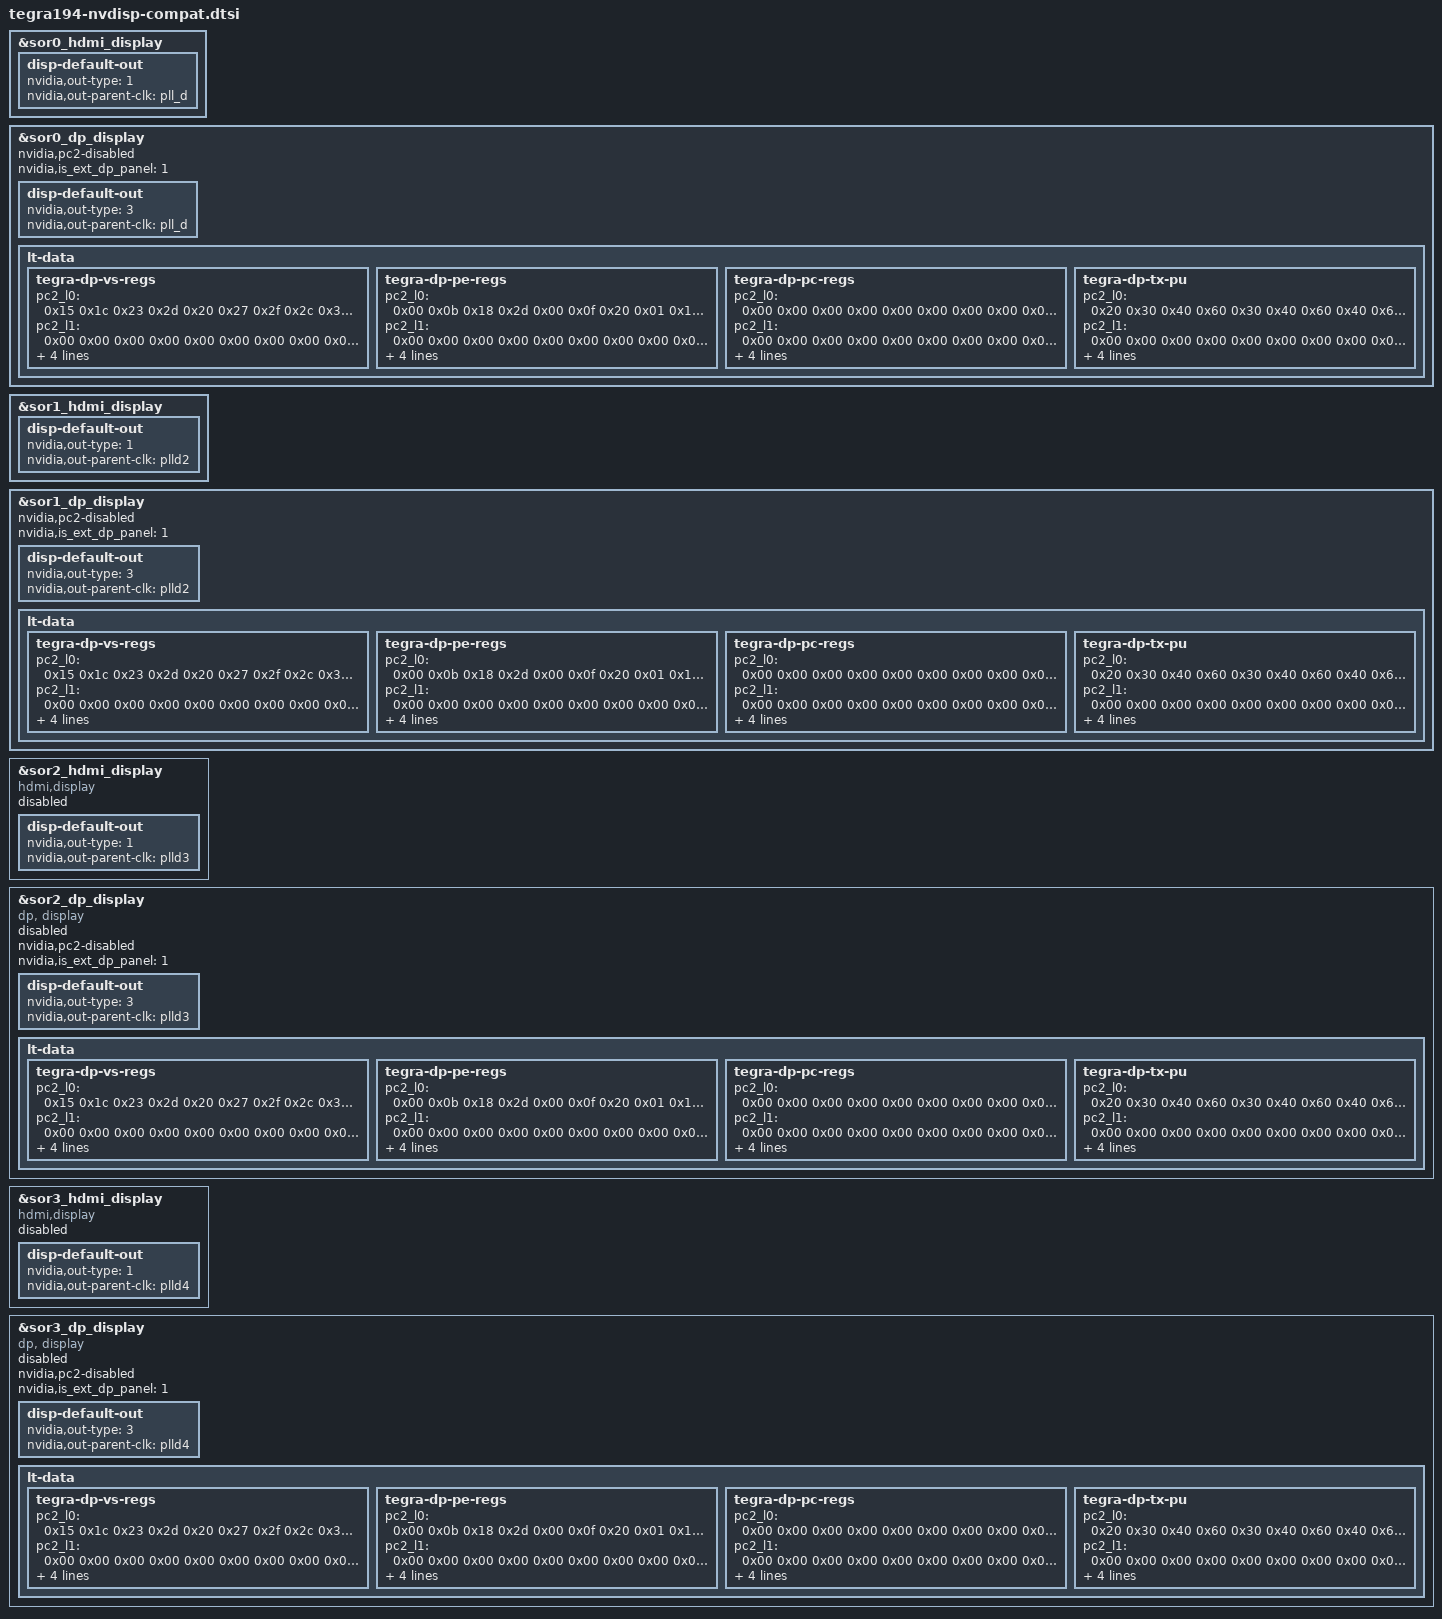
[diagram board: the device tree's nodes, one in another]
/*
 * Copyright (c) 2014-2023, NVIDIA CORPORATION.  All rights reserved.
 *
 * This program is free software; you can redistribute it and/or modify it
 * under the terms and conditions of the GNU General Public License,
 * version 2, as published by the Free Software Foundation.
 *
 * This program is distributed in the hope it will be useful, but WITHOUT
 * ANY WARRANTY; without even the implied warranty of MERCHANTABILITY or
 * FITNESS FOR A PARTICULAR PURPOSE.  See the GNU General Public License for
 * more details.
 *
 * You should have received a copy of the GNU General Public License
 * along with this program.  If not, see <http://www.gnu.org/licenses/>.
 */

/*
 * tegra194-soc-compat.dtsi: Tegra194 soc dtsi file for compatibility nodes
 * only pertaining to nvdisp/cboot display initialization prior to uefi
 */

&sor0_hdmi_display {
	disp-default-out {
		nvidia,out-type = <1>; // TEGRA_DC_OUT_HDMI
		nvidia,out-parent-clk = "pll_d";
	};
};

&sor0_dp_display {
	nvidia,pc2-disabled;
	nvidia,is_ext_dp_panel = <1>;
	disp-default-out {
		nvidia,out-type = <3>; // TEGRA_DC_OUT_DP
		nvidia,out-parent-clk = "pll_d";
	};
	lt-data {
		tegra-dp-vs-regs {
			/* postcursor2 L0 */
			pc2_l0 = <
				/* pre-emphasis: L0, L1, L2, L3 */
				0x15 0x1c 0x23 0x2d /* voltage swing: L0 */
				0x20 0x27 0x2f /* L1 */
				0x2c 0x36 /* L2 */
				0x3c /* L3 */
			>;
			/* postcursor2 L1 - UNUSED */
			pc2_l1 = <
				0x00 0x00 0x00 0x00
				0x00 0x00 0x00
				0x00 0x00
				0x00
			>;
			/* postcursor2 L2 - UNUSED */
			pc2_l2 = <
				0x00 0x00 0x00 0x00
				0x00 0x00 0x00
				0x00 0x00
				0x00
			>;
			/* postcursor2 L3 - UNUSED */
			pc2_l3 = <
				0x00 0x00 0x00 0x00
				0x00 0x00 0x00
				0x00 0x00
				0x00
			>;
		};
		tegra-dp-pe-regs {
			/* postcursor2 L0 */
			pc2_l0 = <
				/* pre-emphasis: L0, L1, L2, L3 */
				0x00 0x0b 0x18 0x2d /* voltage swing: L0 */
				0x00 0x0f 0x20 /* L1 */
				0x01 0x18 /* L2 */
				0x00 /* L3 */
			>;
			/* postcursor2 L1 - UNUSED */
			pc2_l1 = <
				0x00 0x00 0x00 0x00
				0x00 0x00 0x00
				0x00 0x00
				0x00
			>;
			/* postcursor2 L2 - UNUSED */
			pc2_l2 = <
				0x00 0x00 0x00 0x00
				0x00 0x00 0x00
				0x00 0x00
				0x00
			>;
			/* postcursor2 L3 - UNUSED */
			pc2_l3 = <
				0x00 0x00 0x00 0x00
				0x00 0x00 0x00
				0x00 0x00
				0x00
			>;
		};
		tegra-dp-pc-regs {
			/* postcursor2 L0 */
			pc2_l0 = <
				/* pre-emphasis: L0, L1, L2, L3 */
				0x00 0x00 0x00 0x00 /* voltage swing: L0 */
				0x00 0x00 0x00 /* L1 */
				0x00 0x00 /* L2 */
				0x00 /* L3 */
			>;
			/* postcursor2 L1 - UNUSED */
			pc2_l1 = <
				0x00 0x00 0x00 0x00
				0x00 0x00 0x00
				0x00 0x00
				0x00
			>;
			/* postcursor2 L2 - UNUSED */
			pc2_l2 = <
				0x00 0x00 0x00 0x00
				0x00 0x00 0x00
				0x00 0x00
				0x00
			>;
			/* postcursor2 L3 - UNUSED */
			pc2_l3 = <
				0x00 0x00 0x00 0x00
				0x00 0x00 0x00
				0x00 0x00
				0x00
			>;
		};
		tegra-dp-tx-pu {
			/* postcursor2 L0 */
			pc2_l0 = <
				/* pre-emphasis: L0, L1, L2, L3 */
				0x20 0x30 0x40 0x60 /* voltage swing: L0 */
				0x30 0x40 0x60 /* L1 */
				0x40 0x60 /* L2 */
				0x60 /* L3 */
			>;
			/* postcursor2 L1 - UNUSED */
			pc2_l1 = <
				0x00 0x00 0x00 0x00
				0x00 0x00 0x00
				0x00 0x00
				0x00
			>;
			/* postcursor2 L2 - UNUSED */
			pc2_l2 = <
				0x00 0x00 0x00 0x00
				0x00 0x00 0x00
				0x00 0x00
				0x00
			>;
			/* postcursor2 L3 - UNUSED */
			pc2_l3 = <
				0x00 0x00 0x00 0x00
				0x00 0x00 0x00
				0x00 0x00
				0x00
			>;
		};
	};
};

&sor1_hdmi_display {
	disp-default-out {
		nvidia,out-type = <1>; // TEGRA_DC_OUT_HDMI
		nvidia,out-parent-clk = "plld2";
	};
};

&sor1_dp_display {
	nvidia,pc2-disabled;
	nvidia,is_ext_dp_panel = <1>;
	disp-default-out {
		nvidia,out-type = <3>; // TEGRA_DC_OUT_DP
		nvidia,out-parent-clk = "plld2";
	};
	lt-data {
		tegra-dp-vs-regs {
			/* postcursor2 L0 */
			pc2_l0 = <
				/* pre-emphasis: L0, L1, L2, L3 */
				0x15 0x1c 0x23 0x2d /* voltage swing: L0 */
				0x20 0x27 0x2f /* L1 */
				0x2c 0x36 /* L2 */
				0x3c /* L3 */
			>;
			/* postcursor2 L1 - UNUSED */
			pc2_l1 = <
				0x00 0x00 0x00 0x00
				0x00 0x00 0x00
				0x00 0x00
				0x00
			>;
			/* postcursor2 L2 - UNUSED */
			pc2_l2 = <
				0x00 0x00 0x00 0x00
				0x00 0x00 0x00
				0x00 0x00
				0x00
			>;
			/* postcursor2 L3 - UNUSED */
			pc2_l3 = <
				0x00 0x00 0x00 0x00
				0x00 0x00 0x00
				0x00 0x00
				0x00
			>;
		};
		tegra-dp-pe-regs {
			/* postcursor2 L0 */
			pc2_l0 = <
				/* pre-emphasis: L0, L1, L2, L3 */
				0x00 0x0b 0x18 0x2d /* voltage swing: L0 */
				0x00 0x0f 0x20 /* L1 */
				0x01 0x18 /* L2 */
				0x00 /* L3 */
			>;
			/* postcursor2 L1 - UNUSED */
			pc2_l1 = <
				0x00 0x00 0x00 0x00
				0x00 0x00 0x00
				0x00 0x00
				0x00
			>;
			/* postcursor2 L2 - UNUSED */
			pc2_l2 = <
				0x00 0x00 0x00 0x00
				0x00 0x00 0x00
				0x00 0x00
				0x00
			>;
			/* postcursor2 L3 - UNUSED */
			pc2_l3 = <
				0x00 0x00 0x00 0x00
				0x00 0x00 0x00
				0x00 0x00
				0x00
			>;
		};
		tegra-dp-pc-regs {
			/* postcursor2 L0 */
			pc2_l0 = <
				/* pre-emphasis: L0, L1, L2, L3 */
				0x00 0x00 0x00 0x00 /* voltage swing: L0 */
				0x00 0x00 0x00 /* L1 */
				0x00 0x00 /* L2 */
				0x00 /* L3 */
			>;
			/* postcursor2 L1 - UNUSED */
			pc2_l1 = <
				0x00 0x00 0x00 0x00
				0x00 0x00 0x00
				0x00 0x00
				0x00
			>;
			/* postcursor2 L2 - UNUSED */
			pc2_l2 = <
				0x00 0x00 0x00 0x00
				0x00 0x00 0x00
				0x00 0x00
				0x00
			>;
			/* postcursor2 L3 - UNUSED */
			pc2_l3 = <
				0x00 0x00 0x00 0x00
				0x00 0x00 0x00
				0x00 0x00
				0x00
			>;
		};
		tegra-dp-tx-pu {
			/* postcursor2 L0 */
			pc2_l0 = <
				/* pre-emphasis: L0, L1, L2, L3 */
				0x20 0x30 0x40 0x60 /* voltage swing: L0 */
				0x30 0x40 0x60 /* L1 */
				0x40 0x60 /* L2 */
				0x60 /* L3 */
			>;
			/* postcursor2 L1 - UNUSED */
			pc2_l1 = <
				0x00 0x00 0x00 0x00
				0x00 0x00 0x00
				0x00 0x00
				0x00
			>;
			/* postcursor2 L2 - UNUSED */
			pc2_l2 = <
				0x00 0x00 0x00 0x00
				0x00 0x00 0x00
				0x00 0x00
				0x00
			>;
			/* postcursor2 L3 - UNUSED */
			pc2_l3 = <
				0x00 0x00 0x00 0x00
				0x00 0x00 0x00
				0x00 0x00
				0x00
			>;
		};
	};
};

&sor2_hdmi_display {
	compatible = "hdmi,display";
	status = "disabled";
	disp-default-out {
		nvidia,out-type = <1>; // TEGRA_DC_OUT_HDMI
		nvidia,out-parent-clk = "plld3";
	};
};
&sor2_dp_display {
	compatible = "dp, display";
	status = "disabled";
	nvidia,pc2-disabled;
	nvidia,is_ext_dp_panel = <1>;
	disp-default-out {
		nvidia,out-type = <3>; // TEGRA_DC_OUT_DP
		nvidia,out-parent-clk = "plld3";
	};
	lt-data {
		tegra-dp-vs-regs {
			/* postcursor2 L0 */
			pc2_l0 = <
				/* pre-emphasis: L0, L1, L2, L3 */
				0x15 0x1c 0x23 0x2d /* voltage swing: L0 */
				0x20 0x27 0x2f /* L1 */
				0x2c 0x36 /* L2 */
				0x3c /* L3 */
			>;
			/* postcursor2 L1 - UNUSED */
			pc2_l1 = <
				0x00 0x00 0x00 0x00
				0x00 0x00 0x00
				0x00 0x00
				0x00
			>;
			/* postcursor2 L2 - UNUSED */
			pc2_l2 = <
				0x00 0x00 0x00 0x00
				0x00 0x00 0x00
				0x00 0x00
				0x00
			>;
			/* postcursor2 L3 - UNUSED */
			pc2_l3 = <
				0x00 0x00 0x00 0x00
				0x00 0x00 0x00
				0x00 0x00
				0x00
			>;
		};
		tegra-dp-pe-regs {
			/* postcursor2 L0 */
			pc2_l0 = <
				/* pre-emphasis: L0, L1, L2, L3 */
				0x00 0x0b 0x18 0x2d /* voltage swing: L0 */
				0x00 0x0f 0x20 /* L1 */
				0x01 0x18 /* L2 */
				0x00 /* L3 */
			>;
			/* postcursor2 L1 - UNUSED */
			pc2_l1 = <
				0x00 0x00 0x00 0x00
				0x00 0x00 0x00
				0x00 0x00
				0x00
			>;
			/* postcursor2 L2 - UNUSED */
			pc2_l2 = <
				0x00 0x00 0x00 0x00
				0x00 0x00 0x00
				0x00 0x00
				0x00
			>;
			/* postcursor2 L3 - UNUSED */
			pc2_l3 = <
				0x00 0x00 0x00 0x00
				0x00 0x00 0x00
				0x00 0x00
				0x00
			>;
		};
		tegra-dp-pc-regs {
			/* postcursor2 L0 */
			pc2_l0 = <
				/* pre-emphasis: L0, L1, L2, L3 */
				0x00 0x00 0x00 0x00 /* voltage swing: L0 */
				0x00 0x00 0x00 /* L1 */
				0x00 0x00 /* L2 */
				0x00 /* L3 */
			>;
			/* postcursor2 L1 - UNUSED */
			pc2_l1 = <
				0x00 0x00 0x00 0x00
				0x00 0x00 0x00
				0x00 0x00
				0x00
			>;
			/* postcursor2 L2 - UNUSED */
			pc2_l2 = <
				0x00 0x00 0x00 0x00
				0x00 0x00 0x00
				0x00 0x00
				0x00
			>;
			/* postcursor2 L3 - UNUSED */
			pc2_l3 = <
				0x00 0x00 0x00 0x00
				0x00 0x00 0x00
				0x00 0x00
				0x00
			>;
		};
		tegra-dp-tx-pu {
			/* postcursor2 L0 */
			pc2_l0 = <
				/* pre-emphasis: L0, L1, L2, L3 */
				0x20 0x30 0x40 0x60 /* voltage swing: L0 */
				0x30 0x40 0x60 /* L1 */
				0x40 0x60 /* L2 */
				0x60 /* L3 */
			>;
			/* postcursor2 L1 - UNUSED */
			pc2_l1 = <
				0x00 0x00 0x00 0x00
				0x00 0x00 0x00
				0x00 0x00
				0x00
			>;
			/* postcursor2 L2 - UNUSED */
			pc2_l2 = <
				0x00 0x00 0x00 0x00
				0x00 0x00 0x00
				0x00 0x00
				0x00
			>;
			/* postcursor2 L3 - UNUSED */
			pc2_l3 = <
				0x00 0x00 0x00 0x00
				0x00 0x00 0x00
				0x00 0x00
				0x00
			>;
		};
	};
};

&sor3_hdmi_display{
	compatible = "hdmi,display";
	status = "disabled";
	disp-default-out {
		nvidia,out-type = <1>; // TEGRA_DC_OUT_HDMI
		nvidia,out-parent-clk = "plld4";
	};
};

&sor3_dp_display {
	compatible = "dp, display";
	status = "disabled";
	nvidia,pc2-disabled;
	nvidia,is_ext_dp_panel = <1>;
	disp-default-out {
		nvidia,out-type = <3>; // TEGRA_DC_OUT_DP
		nvidia,out-parent-clk = "plld4";
	};
	lt-data {
		tegra-dp-vs-regs {
			/* postcursor2 L0 */
			pc2_l0 = <
				/* pre-emphasis: L0, L1, L2, L3 */
				0x15 0x1c 0x23 0x2d /* voltage swing: L0 */
				0x20 0x27 0x2f /* L1 */
				0x2c 0x36 /* L2 */
				0x3c /* L3 */
			>;
			/* postcursor2 L1 - UNUSED */
			pc2_l1 = <
				0x00 0x00 0x00 0x00
				0x00 0x00 0x00
				0x00 0x00
				0x00
			>;
			/* postcursor2 L2 - UNUSED */
			pc2_l2 = <
				0x00 0x00 0x00 0x00
				0x00 0x00 0x00
				0x00 0x00
				0x00
			>;
			/* postcursor2 L3 - UNUSED */
			pc2_l3 = <
				0x00 0x00 0x00 0x00
				0x00 0x00 0x00
				0x00 0x00
				0x00
			>;
		};
		tegra-dp-pe-regs {
			/* postcursor2 L0 */
			pc2_l0 = <
				/* pre-emphasis: L0, L1, L2, L3 */
				0x00 0x0b 0x18 0x2d /* voltage swing: L0 */
				0x00 0x0f 0x20 /* L1 */
				0x01 0x18 /* L2 */
				0x00 /* L3 */
			>;
			/* postcursor2 L1 - UNUSED */
			pc2_l1 = <
				0x00 0x00 0x00 0x00
				0x00 0x00 0x00
				0x00 0x00
				0x00
			>;
			/* postcursor2 L2 - UNUSED */
			pc2_l2 = <
				0x00 0x00 0x00 0x00
				0x00 0x00 0x00
				0x00 0x00
				0x00
			>;
			/* postcursor2 L3 - UNUSED */
			pc2_l3 = <
				0x00 0x00 0x00 0x00
				0x00 0x00 0x00
				0x00 0x00
				0x00
			>;
		};
		tegra-dp-pc-regs {
			/* postcursor2 L0 */
			pc2_l0 = <
				/* pre-emphasis: L0, L1, L2, L3 */
				0x00 0x00 0x00 0x00 /* voltage swing: L0 */
				0x00 0x00 0x00 /* L1 */
				0x00 0x00 /* L2 */
				0x00 /* L3 */
			>;
			/* postcursor2 L1 - UNUSED */
			pc2_l1 = <
				0x00 0x00 0x00 0x00
				0x00 0x00 0x00
				0x00 0x00
				0x00
			>;
			/* postcursor2 L2 - UNUSED */
			pc2_l2 = <
				0x00 0x00 0x00 0x00
				0x00 0x00 0x00
				0x00 0x00
				0x00
			>;
			/* postcursor2 L3 - UNUSED */
			pc2_l3 = <
				0x00 0x00 0x00 0x00
				0x00 0x00 0x00
				0x00 0x00
				0x00
			>;
		};
		tegra-dp-tx-pu {
			/* postcursor2 L0 */
			pc2_l0 = <
				/* pre-emphasis: L0, L1, L2, L3 */
				0x20 0x30 0x40 0x60 /* voltage swing: L0 */
				0x30 0x40 0x60 /* L1 */
				0x40 0x60 /* L2 */
				0x60 /* L3 */
			>;
			/* postcursor2 L1 - UNUSED */
			pc2_l1 = <
				0x00 0x00 0x00 0x00
				0x00 0x00 0x00
				0x00 0x00
				0x00
			>;
			/* postcursor2 L2 - UNUSED */
			pc2_l2 = <
				0x00 0x00 0x00 0x00
				0x00 0x00 0x00
				0x00 0x00
				0x00
			>;
			/* postcursor2 L3 - UNUSED */
			pc2_l3 = <
				0x00 0x00 0x00 0x00
				0x00 0x00 0x00
				0x00 0x00
				0x00
			>;
		};
	};
};
